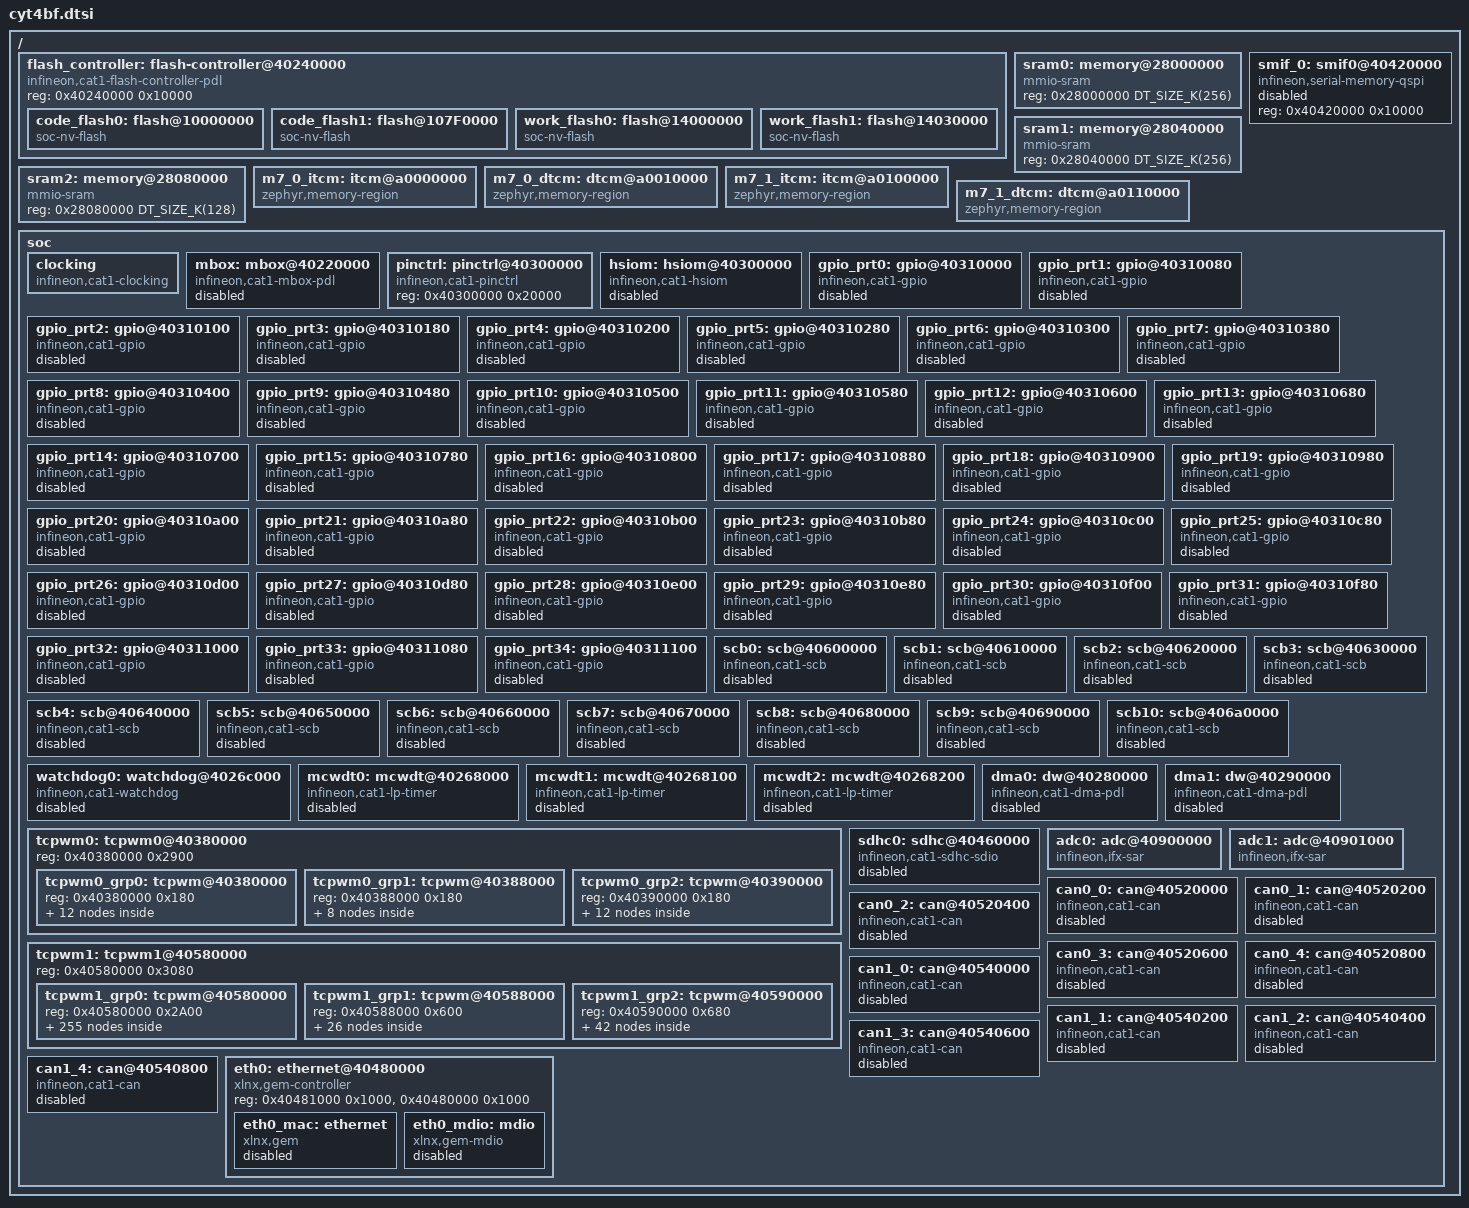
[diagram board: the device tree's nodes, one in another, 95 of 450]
/*
 * Copyright (c) 2023 Cypress Semiconductor Corporation (an Infineon company) or
 * an affiliate of Cypress Semiconductor Corporation
 *
 * SPDX-License-Identifier: Apache-2.0
 */

#include <mem.h>
#include <zephyr/dt-bindings/pinctrl/ifx_cat1-pinctrl.h>
#include <zephyr/dt-bindings/ethernet/xlnx_gem.h>
#include <zephyr/dt-bindings/memory-attr/memory-attr-arm.h>

/ {
	flash_controller: flash-controller@40240000 {
		compatible = "infineon,cat1-flash-controller-pdl";
		reg = <0x40240000 0x10000>;
		#address-cells = <1>;
		#size-cells = <1>;
		status = "okay";

		/* Code flash - Large sector (32KB Sectors) */
		code_flash0: flash@10000000 {
			compatible = "soc-nv-flash";
			reg = <0x10000000 DT_SIZE_K(8128)>;
			write-block-size = <512>;
			erase-block-size = <32768>;
		};

		/* Code flash - Large sector (8KB Sectors) */
		code_flash1: flash@107F0000 {
			compatible = "soc-nv-flash";
			reg = <0x107F0000 DT_SIZE_K(256)>;
			write-block-size = <512>;
			erase-block-size = <8192>;
		};

		/* Work flash - Large sector (2KB Sectors) */
		work_flash0: flash@14000000 {
			compatible = "soc-nv-flash";
			reg = <0x14000000 DT_SIZE_K(192)>;
			write-block-size = <64>;
			erase-block-size = <2048>;
		};

		/* Work flash - Small sector (128B Sectors) */
		work_flash1: flash@14030000 {
			compatible = "soc-nv-flash";
			reg = <0x14030000 DT_SIZE_K(64)>;
			write-block-size = <64>;
			erase-block-size = <128>;
		};
	};

	sram0: memory@28000000 {
		compatible = "mmio-sram";
		reg = <0x28000000 DT_SIZE_K(256)>;
	};
	sram1: memory@28040000 {
		compatible = "mmio-sram";
		reg = <0x28040000 DT_SIZE_K(256)>;
	};
	sram2: memory@28080000 {
		compatible = "mmio-sram";
		reg = <0x28080000 DT_SIZE_K(128)>;
	};

	smif_0: smif0@40420000 {
		compatible = "infineon,serial-memory-qspi";
		reg = <0x40420000 0x10000>;
		#address-cells = <1>;
		#size-cells = <1>;
		status = "disabled";
	};

	m7_0_itcm: itcm@a0000000 {
		compatible = "zephyr,memory-region", "arm,itcm";
		reg = <0xa0000000 DT_SIZE_K(64)>;
		zephyr,memory-region = "M7_0_ITCM";
	};
	m7_0_dtcm: dtcm@a0010000 {
		compatible = "zephyr,memory-region", "arm,dtcm";
		reg = <0xa0010000 DT_SIZE_K(64)>;
		zephyr,memory-region = "M7_0_DTCM";
	};
	m7_1_itcm: itcm@a0100000 {
		compatible = "zephyr,memory-region", "arm,itcm";
		reg = <0xA0100000 DT_SIZE_K(64)>;
		zephyr,memory-region = "M7_1_ITCM";
	};
	m7_1_dtcm: dtcm@a0110000 {
		compatible = "zephyr,memory-region", "arm,dtcm";
		reg = <0xA0110000 DT_SIZE_K(64)>;
		zephyr,memory-region = "M7_1_DTCM";
	};

	soc {
		clocking: clocking {
			compatible = "infineon,cat1-clocking";
		};

		mbox: mbox@40220000 {
			compatible = "infineon,cat1-mbox-pdl";
			reg = <0x40220000 0x10000>;
			system-interrupts = <0 3>;
			#mbox-cells = <1>;
			status = "disabled";
		};

		pinctrl: pinctrl@40300000 {
			compatible = "infineon,cat1-pinctrl";
			reg = <0x40300000 0x20000>;
		};
		hsiom: hsiom@40300000 {
			compatible = "infineon,cat1-hsiom";
			reg = <0x40300000 0x4000>;
			system-interrupts = <21 6>, <20 6>;
			status = "disabled";
		};

		gpio_prt0: gpio@40310000 {
			compatible = "infineon,cat1-gpio";
			reg = <0x40310000 0x80>;
			system-interrupts = <22 2>;
			gpio-controller;
			ngpios = <4>;
			status = "disabled";
			#gpio-cells = <2>;
		};
		gpio_prt1: gpio@40310080 {
			compatible = "infineon,cat1-gpio";
			reg = <0x40310080 0x80>;
			system-interrupts = <23 2>;
			gpio-controller;
			ngpios = <7>;
			status = "disabled";
			#gpio-cells = <2>;
		};
		gpio_prt2: gpio@40310100 {
			compatible = "infineon,cat1-gpio";
			reg = <0x40310100 0x80>;
			system-interrupts = <24 2>;
			gpio-controller;
			ngpios = <8>;
			status = "disabled";
			#gpio-cells = <2>;
		};
		gpio_prt3: gpio@40310180 {
			compatible = "infineon,cat1-gpio";
			reg = <0x40310180 0x80>;
			system-interrupts = <25 2>;
			gpio-controller;
			ngpios = <8>;
			status = "disabled";
			#gpio-cells = <2>;
		};
		gpio_prt4: gpio@40310200 {
			compatible = "infineon,cat1-gpio";
			reg = <0x40310200 0x80>;
			system-interrupts = <26 2>;
			gpio-controller;
			ngpios = <7>;
			status = "disabled";
			#gpio-cells = <2>;
		};
		gpio_prt5: gpio@40310280 {
			compatible = "infineon,cat1-gpio";
			reg = <0x40310280 0x80>;
			system-interrupts = <27 2>;
			gpio-controller;
			ngpios = <6>;
			status = "disabled";
			#gpio-cells = <2>;
		};
		gpio_prt6: gpio@40310300 {
			compatible = "infineon,cat1-gpio";
			reg = <0x40310300 0x80>;
			system-interrupts = <28 2>;
			gpio-controller;
			ngpios = <8>;
			status = "disabled";
			#gpio-cells = <2>;
		};
		gpio_prt7: gpio@40310380 {
			compatible = "infineon,cat1-gpio";
			reg = <0x40310380 0x80>;
			system-interrupts = <29 2>;
			gpio-controller;
			ngpios = <8>;
			status = "disabled";
			#gpio-cells = <2>;
		};
		gpio_prt8: gpio@40310400 {
			compatible = "infineon,cat1-gpio";
			reg = <0x40310400 0x80>;
			system-interrupts = <30 2>;
			gpio-controller;
			ngpios = <5>;
			status = "disabled";
			#gpio-cells = <2>;
		};
		gpio_prt9: gpio@40310480 {
			compatible = "infineon,cat1-gpio";
			reg = <0x40310480 0x80>;
			system-interrupts = <31 2>;
			gpio-controller;
			ngpios = <4>;
			status = "disabled";
			#gpio-cells = <2>;
		};
		gpio_prt10: gpio@40310500 {
			compatible = "infineon,cat1-gpio";
			reg = <0x40310500 0x80>;
			system-interrupts = <32 2>;
			gpio-controller;
			ngpios = <8>;
			status = "disabled";
			#gpio-cells = <2>;
		};
		gpio_prt11: gpio@40310580 {
			compatible = "infineon,cat1-gpio";
			reg = <0x40310580 0x80>;
			system-interrupts = <33 2>;
			gpio-controller;
			ngpios = <3>;
			status = "disabled";
			#gpio-cells = <2>;
		};
		gpio_prt12: gpio@40310600 {
			compatible = "infineon,cat1-gpio";
			reg = <0x40310600 0x80>;
			system-interrupts = <34 2>;
			gpio-controller;
			ngpios = <8>;
			status = "disabled";
			#gpio-cells = <2>;
		};
		gpio_prt13: gpio@40310680 {
			compatible = "infineon,cat1-gpio";
			reg = <0x40310680 0x80>;
			system-interrupts = <35 2>;
			gpio-controller;
			ngpios = <8>;
			status = "disabled";
			#gpio-cells = <2>;
		};
		gpio_prt14: gpio@40310700 {
			compatible = "infineon,cat1-gpio";
			reg = <0x40310700 0x80>;
			system-interrupts = <36 2>;
			gpio-controller;
			ngpios = <8>;
			status = "disabled";
			#gpio-cells = <2>;
		};
		gpio_prt15: gpio@40310780 {
			compatible = "infineon,cat1-gpio";
			reg = <0x40310780 0x80>;
			system-interrupts = <37 2>;
			gpio-controller;
			ngpios = <4>;
			status = "disabled";
			#gpio-cells = <2>;
		};
		gpio_prt16: gpio@40310800 {
			compatible = "infineon,cat1-gpio";
			reg = <0x40310800 0x80>;
			system-interrupts = <38 2>;
			gpio-controller;
			ngpios = <8>;
			status = "disabled";
			#gpio-cells = <2>;
		};
		gpio_prt17: gpio@40310880 {
			compatible = "infineon,cat1-gpio";
			reg = <0x40310880 0x80>;
			system-interrupts = <39 2>;
			gpio-controller;
			ngpios = <8>;
			status = "disabled";
			#gpio-cells = <2>;
		};
		gpio_prt18: gpio@40310900 {
			compatible = "infineon,cat1-gpio";
			reg = <0x40310900 0x80>;
			system-interrupts = <40 2>;
			gpio-controller;
			ngpios = <8>;
			status = "disabled";
			#gpio-cells = <2>;
		};
		gpio_prt19: gpio@40310980 {
			compatible = "infineon,cat1-gpio";
			reg = <0x40310980 0x80>;
			system-interrupts = <41 2>;
			gpio-controller;
			ngpios = <5>;
			status = "disabled";
			#gpio-cells = <2>;
		};
		gpio_prt20: gpio@40310a00 {
			compatible = "infineon,cat1-gpio";
			reg = <0x40310a00 0x80>;
			system-interrupts = <42 2>;
			gpio-controller;
			ngpios = <8>;
			status = "disabled";
			#gpio-cells = <2>;
		};
		gpio_prt21: gpio@40310a80 {
			compatible = "infineon,cat1-gpio";
			reg = <0x40310a80 0x80>;
			system-interrupts = <43 2>;
			gpio-controller;
			ngpios = <8>;
			status = "disabled";
			#gpio-cells = <2>;
		};
		gpio_prt22: gpio@40310b00 {
			compatible = "infineon,cat1-gpio";
			reg = <0x40310b00 0x80>;
			system-interrupts = <44 2>;
			gpio-controller;
			ngpios = <7>;
			status = "disabled";
			#gpio-cells = <2>;
		};
		gpio_prt23: gpio@40310b80 {
			compatible = "infineon,cat1-gpio";
			reg = <0x40310b80 0x80>;
			system-interrupts = <45 2>;
			gpio-controller;
			ngpios = <8>;
			status = "disabled";
			#gpio-cells = <2>;
		};
		gpio_prt24: gpio@40310c00 {
			compatible = "infineon,cat1-gpio";
			reg = <0x40310c00 0x80>;
			system-interrupts = <52 2>;
			gpio-controller;
			ngpios = <5>;
			status = "disabled";
			#gpio-cells = <2>;
		};
		gpio_prt25: gpio@40310c80 {
			compatible = "infineon,cat1-gpio";
			reg = <0x40310c80 0x80>;
			system-interrupts = <53 2>;
			gpio-controller;
			ngpios = <8>;
			status = "disabled";
			#gpio-cells = <2>;
		};
		gpio_prt26: gpio@40310d00 {
			compatible = "infineon,cat1-gpio";
			reg = <0x40310d00 0x80>;
			system-interrupts = <54 2>;
			gpio-controller;
			ngpios = <8>;
			status = "disabled";
			#gpio-cells = <2>;
		};
		gpio_prt27: gpio@40310d80 {
			compatible = "infineon,cat1-gpio";
			reg = <0x40310d80 0x80>;
			system-interrupts = <55 2>;
			gpio-controller;
			ngpios = <8>;
			status = "disabled";
			#gpio-cells = <2>;
		};
		gpio_prt28: gpio@40310e00 {
			compatible = "infineon,cat1-gpio";
			reg = <0x40310e00 0x80>;
			system-interrupts = <46 2>;
			gpio-controller;
			ngpios = <8>;
			status = "disabled";
			#gpio-cells = <2>;
		};
		gpio_prt29: gpio@40310e80 {
			compatible = "infineon,cat1-gpio";
			reg = <0x40310e80 0x80>;
			system-interrupts = <47 2>;
			gpio-controller;
			ngpios = <8>;
			status = "disabled";
			#gpio-cells = <2>;
		};
		gpio_prt30: gpio@40310f00 {
			compatible = "infineon,cat1-gpio";
			reg = <0x40310f00 0x80>;
			system-interrupts = <48 2>;
			gpio-controller;
			ngpios = <4>;
			status = "disabled";
			#gpio-cells = <2>;
		};
		gpio_prt31: gpio@40310f80 {
			compatible = "infineon,cat1-gpio";
			reg = <0x40310f80 0x80>;
			system-interrupts = <49 2>;
			gpio-controller;
			ngpios = <3>;
			status = "disabled";
			#gpio-cells = <2>;
		};
		gpio_prt32: gpio@40311000 {
			compatible = "infineon,cat1-gpio";
			reg = <0x40311000 0x80>;
			system-interrupts = <50 2>;
			gpio-controller;
			ngpios = <8>;
			status = "disabled";
			#gpio-cells = <2>;
		};
		gpio_prt33: gpio@40311080 {
			compatible = "infineon,cat1-gpio";
			reg = <0x40311080 0x80>;
			system-interrupts = <56 2>;
			gpio-controller;
			ngpios = <8>;
			status = "disabled";
			#gpio-cells = <2>;
		};
		gpio_prt34: gpio@40311100 {
			compatible = "infineon,cat1-gpio";
			reg = <0x40311100 0x80>;
			system-interrupts = <57 2>;
			gpio-controller;
			ngpios = <8>;
			status = "disabled";
			#gpio-cells = <2>;
		};

		scb0: scb@40600000 {
			compatible = "infineon,cat1-scb";
			reg = <0x40600000 0xfd0>;
			system-interrupts = <18 6>;
			status = "disabled";
		};
		scb1: scb@40610000 {
			compatible = "infineon,cat1-scb";
			reg = <0x40610000 0xfd0>;
			system-interrupts = <113 6>;
			status = "disabled";
		};
		scb2: scb@40620000 {
			compatible = "infineon,cat1-scb";
			reg = <0x40620000 0xfd0>;
			system-interrupts = <114 6>;
			status = "disabled";
		};
		scb3: scb@40630000 {
			compatible = "infineon,cat1-scb";
			reg = <0x40630000 0xfd0>;
			system-interrupts = <115 6>;
			status = "disabled";
		};
		scb4: scb@40640000 {
			compatible = "infineon,cat1-scb";
			reg = <0x40640000 0xfd0>;
			system-interrupts = <116 6>;
			status = "disabled";
		};
		scb5: scb@40650000 {
			compatible = "infineon,cat1-scb";
			reg = <0x40650000 0xfd0>;
			system-interrupts = <117 6>;
			status = "disabled";
		};
		scb6: scb@40660000 {
			compatible = "infineon,cat1-scb";
			reg = <0x40660000 0xfd0>;
			system-interrupts = <118 6>;
			status = "disabled";
		};
		scb7: scb@40670000 {
			compatible = "infineon,cat1-scb";
			reg = <0x40670000 0xfd0>;
			system-interrupts = <119 6>;
			status = "disabled";
		};
		scb8: scb@40680000 {
			compatible = "infineon,cat1-scb";
			reg = <0x40680000 0xfd0>;
			system-interrupts = <120 6>;
			status = "disabled";
		};
		scb9: scb@40690000 {
			compatible = "infineon,cat1-scb";
			reg = <0x40690000 0xfd0>;
			system-interrupts = <121 6>;
			status = "disabled";
		};
		scb10: scb@406a0000 {
			compatible = "infineon,cat1-scb";
			reg = <0x406a0000 0xfd0>;
			system-interrupts = <122 6>;
			status = "disabled";
		};

		watchdog0: watchdog@4026c000 {
			compatible = "infineon,cat1-watchdog";
			reg = <0x4026c000 0x80>;
			system-interrupts = <16 6>;
			status = "disabled";
		};

		mcwdt0: mcwdt@40268000 {
			compatible = "infineon,cat1-lp-timer";
			reg = <0x40268000 0x100>;
			system-interrupts = <13 6>;
			status = "disabled";
		};
		mcwdt1: mcwdt@40268100 {
			compatible = "infineon,cat1-lp-timer";
			reg = <0x40268100 0x100>;
			system-interrupts = <14 6>;
			status = "disabled";
		};
		mcwdt2: mcwdt@40268200 {
			compatible = "infineon,cat1-lp-timer";
			reg = <0x40268200 0x100>;
			system-interrupts = <15 6>;
			status = "disabled";
		};

			tcpwm0: tcpwm0@40380000 {
			reg = <0x40380000 0x2900>;
			#address-cells = <1>;
			#size-cells = <1>;
			tcpwm0_grp0: tcpwm@40380000 {
				reg = <0x40380000 0x180>;
				#address-cells = <1>;
				#size-cells = <1>;
				tcpwm0_grp0_pwm: pwm@40380000 {
					compatible = "infineon,cat1-pwm";
					reg = <0x40380000 0x180>;
					#address-cells = <1>;
					#size-cells = <0>;
					#pwm-cells = <3>;
					resolution = <16>;
					status = "disabled";

					pwm_ch0_0: channel@0 {
						reg = <0x0>;
						system-interrupts = <519 4>;
						status = "disabled";
					};

					pwm_ch0_1: channel@1 {
						reg = <0x1>;
						system-interrupts = <520 4>;
						status = "disabled";
					};

					pwm_ch0_2: channel@2 {
						reg = <0x2>;
						system-interrupts = <521 4>;
						status = "disabled";
					};
				};

				tcpwm0_grp0_tgpio: tgpio@40380000 {
					compatible = "infineon,tcpwm-tgpio";
					reg = <0x40380000 0x180>;
					#address-cells = <1>;
					#size-cells = <0>;
					status = "disabled";

					tgpio_ch0_0: channel@0 {
						reg = <0x0>;
						system-interrupts = <519 4>;
						status = "disabled";
					};

					tgpio_ch0_1: channel@1 {
						reg = <0x1>;
						system-interrupts = <520 4>;
						status = "disabled";
					};

					tgpio_ch0_2: channel@2 {
						reg = <0x2>;
						system-interrupts = <521 4>;
						status = "disabled";
					};
				};
				tcpwm0_grp0_cnt: tcpwm@40380000 {
					compatible = "infineon,tcpwm";
					reg = <0x40380000 0x180>;
					#address-cells = <1>;
					#size-cells = <1>;
					resolution = <16>;
					status = "disabled";

					counter0_0: counter@40380000 {
						compatible = "infineon,tcpwm-counter";
						reg = <0x40380000 0x80>;
						system-interrupts = <519 4>;
						status = "disabled";
					};

					counter0_1: counter@40380080 {
						compatible = "infineon,tcpwm-counter";
						reg = <0x40380080 0x80>;
						system-interrupts = <520 4>;
						status = "disabled";
					};

					counter0_2: counter@40380100 {
						compatible = "infineon,tcpwm-counter";
						reg = <0x40380100 0x80>;
						system-interrupts = <521 4>;
						status = "disabled";
					};
				};
			};
			tcpwm0_grp1: tcpwm@40388000 {
				reg = <0x40388000 0x180>;
				#address-cells = <1>;
				#size-cells = <1>;
				tcpwm0_grp1_pwm: pwm@40388000 {
					compatible = "infineon,cat1-pwm";
					reg = <0x40388000 0x180>;
					#address-cells = <1>;
					#size-cells = <0>;
					#pwm-cells = <3>;
					resolution = <16>;
					status = "disabled";

					pwm_ch1_0: channel@0 {
						reg = <0x0>;
						system-interrupts = <534 4>;
						status = "disabled";
					};

					pwm_ch1_1: channel@1 {
						reg = <0x1>;
						system-interrupts = <535 4>;
						status = "disabled";
					};

					pwm_ch1_2: channel@2 {
						reg = <0x2>;
						system-interrupts = <536 4>;
						status = "disabled";
					};
				};

			tcpwm0_grp1_cnt: tcpwm@40388000 {
					compatible = "infineon,tcpwm";
					reg = <0x40388000 0x180>;
					#address-cells = <1>;
					#size-cells = <1>;
					resolution = <16>;
					status = "disabled";

					counter1_0: counter@40388000 {
						compatible = "infineon,tcpwm-counter";
						reg = <0x40388000 0x80>;
						system-interrupts = <534 4>;
						status = "disabled";
					};

					counter1_1: counter@40388080 {
						compatible = "infineon,tcpwm-counter";
						reg = <0x40388080 0x80>;
						system-interrupts = <535 4>;
						status = "disabled";
					};

					counter1_2: counter@40388100 {
						compatible = "infineon,tcpwm-counter";
						reg = <0x40388100 0x80>;
						system-interrupts = <536 4>;
						status = "disabled";
					};
				};
			};

			tcpwm0_grp2: tcpwm@40390000 {
				reg = <0x40390000 0x180>;
				#address-cells = <1>;
				#size-cells = <1>;
				tcpwm0_grp2_pwm: pwm@40390000 {
					compatible = "infineon,cat1-pwm";
					reg = <0x40390000 0x180>;
					#address-cells = <1>;
					#size-cells = <0>;
					#pwm-cells = <3>;
					resolution = <32>;
					status = "disabled";

					pwm_ch2_0: channel@0 {
						reg = <0x0>;
						system-interrupts = <550 4>;
						status = "disabled";
					};

					pwm_ch2_1: channel@1 {
						reg = <0x1>;
						system-interrupts = <551 4>;
						status = "disabled";
					};

					pwm_ch2_2: channel@2 {
						reg = <0x2>;
						system-interrupts = <552 4>;
						status = "disabled";
					};
				};

				tcpwm0_grp2_tgpio: tgpio@40390000 {
					compatible = "infineon,tcpwm-tgpio";
					reg = <0x40390000 0x180>;
					#address-cells = <1>;
					#size-cells = <0>;
					status = "disabled";

					tgpio_ch2_0: channel@0 {
						reg = <0x0>;
						system-interrupts = <550 4>;
						status = "disabled";
					};

					tgpio_ch2_1: channel@1 {
						reg = <0x1>;
						system-interrupts = <551 4>;
						status = "disabled";
					};

					tgpio_ch2_2: channel@2 {
						reg = <0x2>;
						system-interrupts = <552 4>;
						status = "disabled";
					};
				};
			tcpwm0_grp2_cnt: tcpwm@40390000 {
					compatible = "infineon,tcpwm";
					reg = <0x40390000 0x180>;
					#address-cells = <1>;
					#size-cells = <1>;
					resolution = <32>;
					status = "disabled";

					counter2_0: counter@40390000 {
						compatible = "infineon,tcpwm-counter";
						reg = <0x40390000 0x80>;
						system-interrupts = <550 4>;
						status = "disabled";
					};

					counter2_1: counter@40390080 {
						compatible = "infineon,tcpwm-counter";
						reg = <0x40390080 0x80>;
						system-interrupts = <551 4>;
						status = "disabled";
					};

					counter2_2: counter@40390100 {
						compatible = "infineon,tcpwm-counter";
						reg = <0x40390100 0x80>;
						system-interrupts = <552 4>;
						status = "disabled";
					};
				};
			};
		};


		tcpwm1: tcpwm1@40580000 {
			reg = <0x40580000 0x3080>;
			#address-cells = <1>;
			#size-cells = <1>;
			tcpwm1_grp0: tcpwm@40580000 {
				reg = <0x40580000 0x2A00>;
				#address-cells = <1>;
				#size-cells = <1>;
				tcpwm1_grp0_pwm: pwm@40580000 {
					compatible = "infineon,cat1-pwm";
					reg = <0x40580000 0x2A00>;
					#address-cells = <1>;
					#size-cells = <0>;
					#pwm-cells = <3>;
					resolution = <16>;
					status = "disabled";

					pwm1_ch0_0: channel@0 {
						reg = <0x0>;
						system-interrupts = <435 4>;
						status = "disabled";
					};

					pwm1_ch0_1: channel@1 {
						reg = <0x1>;
						system-interrupts = <436 4>;
						status = "disabled";
					};

					pwm1_ch0_2: channel@2 {
						reg = <0x2>;
						system-interrupts = <437 4>;
						status = "disabled";
					};

					pwm1_ch0_3: channel@3 {
						reg = <0x3>;
						system-interrupts = <438 4>;
						status = "disabled";
					};

					pwm1_ch0_4: channel@4 {
						reg = <0x4>;
						system-interrupts = <439 4>;
						status = "disabled";
					};

					pwm1_ch0_5: channel@5 {
						reg = <0x5>;
						system-interrupts = <440 4>;
						status = "disabled";
					};

					pwm1_ch0_6: channel@6 {
						reg = <0x6>;
						system-interrupts = <441 4>;
						status = "disabled";
					};

					pwm1_ch0_7: channel@7 {
						reg = <0x7>;
						system-interrupts = <442 4>;
						status = "disabled";
					};

					pwm1_ch0_8: channel@8 {
						reg = <0x8>;
						system-interrupts = <443 4>;
						status = "disabled";
					};

					pwm1_ch0_9: channel@9 {
						reg = <0x9>;
						system-interrupts = <444 4>;
						status = "disabled";
					};

					pwm1_ch0_10: channel@10 {
						reg = <0xA>;
						system-interrupts = <445 4>;
						status = "disabled";
					};

					pwm1_ch0_11: channel@11 {
						reg = <0xB>;
						system-interrupts = <446 4>;
						status = "disabled";
					};

					pwm1_ch0_12: channel@12 {
						reg = <0xC>;
						system-interrupts = <447 4>;
						status = "disabled";
					};

					pwm1_ch0_13: channel@13 {
						reg = <0xD>;
						system-interrupts = <448 4>;
						status = "disabled";
					};

					pwm1_ch0_14: channel@14 {
						reg = <0xE>;
						system-interrupts = <449 4>;
						status = "disabled";
					};

					pwm1_ch0_15: channel@15 {
						reg = <0xF>;
						system-interrupts = <450 4>;
						status = "disabled";
					};

					pwm1_ch0_16: channel@16 {
						reg = <0x10>;
						system-interrupts = <451 4>;
						status = "disabled";
					};

					pwm1_ch0_17: channel@17 {
						reg = <0x11>;
						system-interrupts = <452 4>;
						status = "disabled";
					};

					pwm1_ch0_18: channel@18 {
						reg = <0x12>;
						system-interrupts = <453 4>;
						status = "disabled";
					};

					pwm1_ch0_19: channel@19 {
						reg = <0x13>;
						system-interrupts = <454 4>;
						status = "disabled";
					};

					pwm1_ch0_20: channel@20 {
						reg = <0x14>;
						system-interrupts = <455 4>;
						status = "disabled";
					};

					pwm1_ch0_21: channel@21 {
						reg = <0x15>;
						system-interrupts = <456 4>;
						status = "disabled";
					};

					pwm1_ch0_22: channel@22 {
						reg = <0x16>;
						system-interrupts = <457 4>;
						status = "disabled";
					};

					pwm1_ch0_23: channel@23 {
						reg = <0x17>;
						system-interrupts = <458 4>;
						status = "disabled";
					};

					pwm1_ch0_24: channel@24 {
						reg = <0x18>;
						system-interrupts = <459 4>;
						status = "disabled";
					};

					pwm1_ch0_25: channel@25 {
						reg = <0x19>;
						system-interrupts = <460 4>;
						status = "disabled";
					};

					pwm1_ch0_26: channel@26 {
						reg = <0x1A>;
						system-interrupts = <461 4>;
						status = "disabled";
					};

					pwm1_ch0_27: channel@27 {
						reg = <0x1B>;
						system-interrupts = <462 4>;
						status = "disabled";
					};

					pwm1_ch0_28: channel@28 {
						reg = <0x1C>;
						system-interrupts = <463 4>;
						status = "disabled";
					};

					pwm1_ch0_29: channel@29 {
						reg = <0x1D>;
						system-interrupts = <464 4>;
						status = "disabled";
					};

					pwm1_ch0_30: channel@30 {
						reg = <0x1E>;
						system-interrupts = <465 4>;
						status = "disabled";
					};

					pwm1_ch0_31: channel@31 {
						reg = <0x1F>;
						system-interrupts = <466 4>;
						status = "disabled";
					};

					pwm1_ch0_32: channel@32 {
						reg = <0x20>;
						system-interrupts = <467 4>;
						status = "disabled";
					};

					pwm1_ch0_33: channel@33 {
						reg = <0x21>;
						system-interrupts = <468 4>;
						status = "disabled";
					};

					pwm1_ch0_34: channel@34 {
						reg = <0x22>;
						system-interrupts = <469 4>;
						status = "disabled";
					};

					pwm1_ch0_35: channel@35 {
						reg = <0x23>;
						system-interrupts = <470 4>;
						status = "disabled";
					};

					pwm1_ch0_36: channel@36 {
						reg = <0x24>;
						system-interrupts = <471 4>;
						status = "disabled";
					};

					pwm1_ch0_37: channel@37 {
						reg = <0x25>;
						system-interrupts = <472 4>;
						status = "disabled";
					};

					pwm1_ch0_38: channel@38 {
						reg = <0x26>;
						system-interrupts = <473 4>;
						status = "disabled";
					};

					pwm1_ch0_39: channel@39 {
						reg = <0x27>;
						system-interrupts = <474 4>;
						status = "disabled";
					};

					pwm1_ch0_40: channel@40 {
						reg = <0x28>;
						system-interrupts = <475 4>;
						status = "disabled";
					};

					pwm1_ch0_41: channel@41 {
						reg = <0x29>;
						system-interrupts = <476 4>;
						status = "disabled";
					};

					pwm1_ch0_42: channel@42 {
						reg = <0x2A>;
						system-interrupts = <477 4>;
						status = "disabled";
					};

					pwm1_ch0_43: channel@43 {
						reg = <0x2B>;
						system-interrupts = <478 4>;
						status = "disabled";
					};

					pwm1_ch0_44: channel@44 {
						reg = <0x2C>;
						system-interrupts = <479 4>;
						status = "disabled";
					};

					pwm1_ch0_45: channel@45 {
						reg = <0x2D>;
						system-interrupts = <480 4>;
						status = "disabled";
					};

					pwm1_ch0_46: channel@46 {
						reg = <0x2E>;
						system-interrupts = <481 4>;
						status = "disabled";
					};

					pwm1_ch0_47: channel@47 {
						reg = <0x2F>;
						system-interrupts = <482 4>;
						status = "disabled";
					};

					pwm1_ch0_48: channel@48 {
						reg = <0x30>;
						system-interrupts = <483 4>;
						status = "disabled";
					};

					pwm1_ch0_49: channel@49 {
						reg = <0x31>;
						system-interrupts = <484 4>;
						status = "disabled";
					};

					pwm1_ch0_50: channel@50 {
						reg = <0x32>;
						system-interrupts = <485 4>;
						status = "disabled";
					};

					pwm1_ch0_51: channel@51 {
						reg = <0x33>;
						system-interrupts = <486 4>;
						status = "disabled";
					};

					pwm1_ch0_52: channel@52 {
						reg = <0x34>;
						system-interrupts = <487 4>;
						status = "disabled";
					};

					pwm1_ch0_53: channel@53 {
						reg = <0x35>;
						system-interrupts = <488 4>;
						status = "disabled";
					};

					pwm1_ch0_54: channel@54 {
						reg = <0x36>;
						system-interrupts = <489 4>;
						status = "disabled";
					};

					pwm1_ch0_55: channel@55 {
						reg = <0x37>;
						system-interrupts = <490 4>;
						status = "disabled";
					};

					pwm1_ch0_56: channel@56 {
						reg = <0x38>;
						system-interrupts = <491 4>;
						status = "disabled";
					};

					pwm1_ch0_57: channel@57 {
						reg = <0x39>;
						system-interrupts = <492 4>;
						status = "disabled";
					};

					pwm1_ch0_58: channel@58 {
						reg = <0x3A>;
						system-interrupts = <493 4>;
						status = "disabled";
					};

					pwm1_ch0_59: channel@59 {
						reg = <0x3B>;
						system-interrupts = <494 4>;
						status = "disabled";
					};

					pwm1_ch0_60: channel@60 {
						reg = <0x3C>;
						system-interrupts = <495 4>;
						status = "disabled";
					};

					pwm1_ch0_61: channel@61 {
						reg = <0x3D>;
						system-interrupts = <496 4>;
						status = "disabled";
					};

					pwm1_ch0_62: channel@62 {
						reg = <0x3E>;
						system-interrupts = <497 4>;
						status = "disabled";
					};

					pwm1_ch0_63: channel@63 {
						reg = <0x3F>;
						system-interrupts = <498 4>;
						status = "disabled";
					};

					pwm1_ch0_64: channel@64 {
						reg = <0x40>;
						system-interrupts = <499 4>;
						status = "disabled";
					};

					pwm1_ch0_65: channel@65 {
						reg = <0x41>;
						system-interrupts = <500 4>;
						status = "disabled";
					};

					pwm1_ch0_66: channel@66 {
						reg = <0x42>;
						system-interrupts = <501 4>;
						status = "disabled";
					};

					pwm1_ch0_67: channel@67 {
						reg = <0x43>;
						system-interrupts = <502 4>;
						status = "disabled";
					};

					pwm1_ch0_68: channel@68 {
						reg = <0x44>;
						system-interrupts = <503 4>;
						status = "disabled";
					};

					pwm1_ch0_69: channel@69 {
						reg = <0x45>;
						system-interrupts = <504 4>;
						status = "disabled";
					};

					pwm1_ch0_70: channel@70 {
						reg = <0x46>;
						system-interrupts = <505 4>;
						status = "disabled";
					};

					pwm1_ch0_71: channel@71 {
						reg = <0x47>;
						system-interrupts = <506 4>;
						status = "disabled";
					};

					pwm1_ch0_72: channel@72 {
						reg = <0x48>;
						system-interrupts = <507 4>;
						status = "disabled";
					};

					pwm1_ch0_73: channel@73 {
						reg = <0x49>;
						system-interrupts = <508 4>;
						status = "disabled";
					};

					pwm1_ch0_74: channel@74 {
						reg = <0x4A>;
						system-interrupts = <509 4>;
						status = "disabled";
					};

					pwm1_ch0_75: channel@75 {
						reg = <0x4B>;
						system-interrupts = <510 4>;
						status = "disabled";
					};

					pwm1_ch0_76: channel@76 {
						reg = <0x4C>;
						system-interrupts = <511 4>;
						status = "disabled";
					};

					pwm1_ch0_77: channel@77 {
						reg = <0x4D>;
						system-interrupts = <512 4>;
						status = "disabled";
					};

					pwm1_ch0_78: channel@78 {
						reg = <0x4E>;
						system-interrupts = <513 4>;
						status = "disabled";
					};

					pwm1_ch0_79: channel@79 {
						reg = <0x4F>;
						system-interrupts = <514 4>;
						status = "disabled";
					};

					pwm1_ch0_80: channel@80 {
						reg = <0x50>;
						system-interrupts = <515 4>;
						status = "disabled";
					};

					pwm1_ch0_81: channel@81 {
						reg = <0x51>;
						system-interrupts = <516 4>;
						status = "disabled";
					};

					pwm1_ch0_82: channel@82 {
						reg = <0x52>;
						system-interrupts = <517 4>;
						status = "disabled";
					};

					pwm1_ch0_83: channel@83 {
						reg = <0x53>;
						system-interrupts = <518 4>;
						status = "disabled";
					};
				};

				tcpwm1_grp0_tgpio: tgpio@40580000 {
					compatible = "infineon,tcpwm-tgpio";
					reg = <0x40580000 0x2A00>;
					#address-cells = <1>;
					#size-cells = <0>;
					status = "disabled";

					tgpio1_ch0_0: channel@0 {
						reg = <0x0>;
						system-interrupts = <435 4>;
						status = "disabled";
					};

					tgpio1_ch0_1: channel@1 {
						reg = <0x1>;
						system-interrupts = <436 4>;
						status = "disabled";
					};

					tgpio1_ch0_2: channel@2 {
						reg = <0x2>;
						system-interrupts = <437 4>;
						status = "disabled";
					};

					tgpio1_ch0_3: channel@3 {
						reg = <0x3>;
						system-interrupts = <438 4>;
						status = "disabled";
					};

					tgpio1_ch0_4: channel@4 {
						reg = <0x4>;
						system-interrupts = <439 4>;
						status = "disabled";
					};

					tgpio1_ch0_5: channel@5 {
						reg = <0x5>;
						system-interrupts = <440 4>;
						status = "disabled";
					};

					tgpio1_ch0_6: channel@6 {
						reg = <0x6>;
						system-interrupts = <441 4>;
						status = "disabled";
					};

					tgpio1_ch0_7: channel@7 {
						reg = <0x7>;
						system-interrupts = <442 4>;
						status = "disabled";
					};

					tgpio1_ch0_8: channel@8 {
						reg = <0x8>;
						system-interrupts = <443 4>;
						status = "disabled";
					};

					tgpio1_ch0_9: channel@9 {
						reg = <0x9>;
						system-interrupts = <444 4>;
						status = "disabled";
					};

					tgpio1_ch0_10: channel@10 {
						reg = <0xA>;
						system-interrupts = <445 4>;
						status = "disabled";
					};

					tgpio1_ch0_11: channel@11 {
						reg = <0xB>;
						system-interrupts = <446 4>;
						status = "disabled";
					};

					tgpio1_ch0_12: channel@12 {
						reg = <0xC>;
						system-interrupts = <447 4>;
						status = "disabled";
					};

					tgpio1_ch0_13: channel@13 {
						reg = <0xD>;
						system-interrupts = <448 4>;
						status = "disabled";
					};

					tgpio1_ch0_14: channel@14 {
						reg = <0xE>;
						system-interrupts = <449 4>;
						status = "disabled";
					};

					tgpio1_ch0_15: channel@15 {
						reg = <0xF>;
						system-interrupts = <450 4>;
						status = "disabled";
					};

					tgpio1_ch0_16: channel@16 {
						reg = <0x10>;
						system-interrupts = <451 4>;
						status = "disabled";
					};

					tgpio1_ch0_17: channel@17 {
						reg = <0x11>;
						system-interrupts = <452 4>;
						status = "disabled";
					};

					tgpio1_ch0_18: channel@18 {
						reg = <0x12>;
						system-interrupts = <453 4>;
						status = "disabled";
					};

					tgpio1_ch0_19: channel@19 {
						reg = <0x13>;
						system-interrupts = <454 4>;
						status = "disabled";
					};

					tgpio1_ch0_20: channel@20 {
						reg = <0x14>;
						system-interrupts = <455 4>;
						status = "disabled";
					};

					tgpio1_ch0_21: channel@21 {
						reg = <0x15>;
						system-interrupts = <456 4>;
						status = "disabled";
					};

					tgpio1_ch0_22: channel@22 {
						reg = <0x16>;
						system-interrupts = <457 4>;
						status = "disabled";
					};

					tgpio1_ch0_23: channel@23 {
						reg = <0x17>;
						system-interrupts = <458 4>;
						status = "disabled";
					};

					tgpio1_ch0_24: channel@24 {
						reg = <0x18>;
						system-interrupts = <459 4>;
						status = "disabled";
					};

					tgpio1_ch0_25: channel@25 {
						reg = <0x19>;
						system-interrupts = <460 4>;
						status = "disabled";
					};

					tgpio1_ch0_26: channel@26 {
						reg = <0x1A>;
						system-interrupts = <461 4>;
						status = "disabled";
					};

					tgpio1_ch0_27: channel@27 {
						reg = <0x1B>;
						system-interrupts = <462 4>;
						status = "disabled";
					};

					tgpio1_ch0_28: channel@28 {
						reg = <0x1C>;
						system-interrupts = <463 4>;
						status = "disabled";
					};

					tgpio1_ch0_29: channel@29 {
						reg = <0x1D>;
						system-interrupts = <464 4>;
						status = "disabled";
					};

					tgpio1_ch0_30: channel@30 {
						reg = <0x1E>;
						system-interrupts = <465 4>;
						status = "disabled";
					};

					tgpio1_ch0_31: channel@31 {
						reg = <0x1F>;
						system-interrupts = <466 4>;
						status = "disabled";
					};

					tgpio1_ch0_32: channel@32 {
						reg = <0x20>;
						system-interrupts = <467 4>;
						status = "disabled";
					};

					tgpio1_ch0_33: channel@33 {
						reg = <0x21>;
						system-interrupts = <468 4>;
						status = "disabled";
					};

					tgpio1_ch0_34: channel@34 {
						reg = <0x22>;
						system-interrupts = <469 4>;
						status = "disabled";
					};

					tgpio1_ch0_35: channel@35 {
						reg = <0x23>;
						system-interrupts = <470 4>;
						status = "disabled";
					};

					tgpio1_ch0_36: channel@36 {
						reg = <0x24>;
						system-interrupts = <471 4>;
						status = "disabled";
					};

					tgpio1_ch0_37: channel@37 {
						reg = <0x25>;
						system-interrupts = <472 4>;
						status = "disabled";
					};

					tgpio1_ch0_38: channel@38 {
						reg = <0x26>;
						system-interrupts = <473 4>;
						status = "disabled";
					};

					tgpio1_ch0_39: channel@39 {
						reg = <0x27>;
						system-interrupts = <474 4>;
						status = "disabled";
					};

					tgpio1_ch0_40: channel@40 {
						reg = <0x28>;
						system-interrupts = <475 4>;
						status = "disabled";
					};

					tgpio1_ch0_41: channel@41 {
						reg = <0x29>;
						system-interrupts = <476 4>;
						status = "disabled";
					};

					tgpio1_ch0_42: channel@42 {
						reg = <0x2A>;
						system-interrupts = <477 4>;
						status = "disabled";
					};

					tgpio1_ch0_43: channel@43 {
						reg = <0x2B>;
						system-interrupts = <478 4>;
						status = "disabled";
					};

					tgpio1_ch0_44: channel@44 {
						reg = <0x2C>;
						system-interrupts = <479 4>;
						status = "disabled";
					};

					tgpio1_ch0_45: channel@45 {
						reg = <0x2D>;
						system-interrupts = <480 4>;
						status = "disabled";
					};

					tgpio1_ch0_46: channel@46 {
						reg = <0x2E>;
						system-interrupts = <481 4>;
						status = "disabled";
					};

					tgpio1_ch0_47: channel@47 {
						reg = <0x2F>;
						system-interrupts = <482 4>;
						status = "disabled";
					};

					tgpio1_ch0_48: channel@48 {
						reg = <0x30>;
						system-interrupts = <483 4>;
						status = "disabled";
					};

					tgpio1_ch0_49: channel@49 {
						reg = <0x31>;
						system-interrupts = <484 4>;
						status = "disabled";
					};

					tgpio1_ch0_50: channel@50 {
						reg = <0x32>;
						system-interrupts = <485 4>;
						status = "disabled";
					};

					tgpio1_ch0_51: channel@51 {
						reg = <0x33>;
						system-interrupts = <486 4>;
						status = "disabled";
					};

					tgpio1_ch0_52: channel@52 {
						reg = <0x34>;
						system-interrupts = <487 4>;
						status = "disabled";
					};

					tgpio1_ch0_53: channel@53 {
						reg = <0x35>;
						system-interrupts = <488 4>;
						status = "disabled";
					};

					tgpio1_ch0_54: channel@54 {
						reg = <0x36>;
						system-interrupts = <489 4>;
						status = "disabled";
					};

					tgpio1_ch0_55: channel@55 {
						reg = <0x37>;
						system-interrupts = <490 4>;
						status = "disabled";
					};

					tgpio1_ch0_56: channel@56 {
						reg = <0x38>;
						system-interrupts = <491 4>;
						status = "disabled";
					};

					tgpio1_ch0_57: channel@57 {
						reg = <0x39>;
						system-interrupts = <492 4>;
						status = "disabled";
					};

					tgpio1_ch0_58: channel@58 {
						reg = <0x3A>;
						system-interrupts = <493 4>;
						status = "disabled";
					};

					tgpio1_ch0_59: channel@59 {
						reg = <0x3B>;
						system-interrupts = <494 4>;
						status = "disabled";
					};

					tgpio1_ch0_60: channel@60 {
						reg = <0x3C>;
						system-interrupts = <495 4>;
						status = "disabled";
					};

					tgpio1_ch0_61: channel@61 {
						reg = <0x3D>;
						system-interrupts = <496 4>;
						status = "disabled";
					};

					tgpio1_ch0_62: channel@62 {
						reg = <0x3E>;
						system-interrupts = <497 4>;
						status = "disabled";
					};

					tgpio1_ch0_63: channel@63 {
						reg = <0x3F>;
						system-interrupts = <498 4>;
						status = "disabled";
					};

					tgpio1_ch0_64: channel@64 {
						reg = <0x40>;
						system-interrupts = <499 4>;
						status = "disabled";
					};

					tgpio1_ch0_65: channel@65 {
						reg = <0x41>;
						system-interrupts = <500 4>;
						status = "disabled";
					};

					tgpio1_ch0_66: channel@66 {
						reg = <0x42>;
						system-interrupts = <501 4>;
						status = "disabled";
					};

					tgpio1_ch0_67: channel@67 {
						reg = <0x43>;
						system-interrupts = <502 4>;
						status = "disabled";
					};

					tgpio1_ch0_68: channel@68 {
						reg = <0x44>;
						system-interrupts = <503 4>;
						status = "disabled";
					};

					tgpio1_ch0_69: channel@69 {
						reg = <0x45>;
						system-interrupts = <504 4>;
						status = "disabled";
					};

					tgpio1_ch0_70: channel@70 {
						reg = <0x46>;
						system-interrupts = <505 4>;
						status = "disabled";
					};

					tgpio1_ch0_71: channel@71 {
						reg = <0x47>;
						system-interrupts = <506 4>;
						status = "disabled";
					};

					tgpio1_ch0_72: channel@72 {
						reg = <0x48>;
						system-interrupts = <507 4>;
						status = "disabled";
					};

					tgpio1_ch0_73: channel@73 {
						reg = <0x49>;
						system-interrupts = <508 4>;
						status = "disabled";
					};

					tgpio1_ch0_74: channel@74 {
						reg = <0x4A>;
						system-interrupts = <509 4>;
						status = "disabled";
					};

					tgpio1_ch0_75: channel@75 {
						reg = <0x4B>;
						system-interrupts = <510 4>;
						status = "disabled";
					};

					tgpio1_ch0_76: channel@76 {
						reg = <0x4C>;
						system-interrupts = <511 4>;
						status = "disabled";
					};

					tgpio1_ch0_77: channel@77 {
						reg = <0x4D>;
						system-interrupts = <512 4>;
						status = "disabled";
					};

					tgpio1_ch0_78: channel@78 {
						reg = <0x4E>;
						system-interrupts = <513 4>;
						status = "disabled";
					};

					tgpio1_ch0_79: channel@79 {
						reg = <0x4F>;
						system-interrupts = <514 4>;
						status = "disabled";
					};

					tgpio1_ch0_80: channel@80 {
						reg = <0x50>;
						system-interrupts = <515 4>;
						status = "disabled";
					};

					tgpio1_ch0_81: channel@81 {
						reg = <0x51>;
						system-interrupts = <516 4>;
						status = "disabled";
					};

					tgpio1_ch0_82: channel@82 {
						reg = <0x52>;
						system-interrupts = <517 4>;
						status = "disabled";
					};

					tgpio1_ch0_83: channel@83 {
						reg = <0x53>;
						system-interrupts = <518 4>;
						status = "disabled";
					};
				};

				tcpwm1_grp0_cnt: tcpwm@40580000 {
					compatible = "infineon,tcpwm";
					reg = <0x40580000 0x2A00>;
					#address-cells = <1>;
					#size-cells = <1>;
					resolution = <16>;
					status = "disabled";

					counter1_0_0: counter@40580000 {
						compatible = "infineon,tcpwm-counter";
						reg = <0x40580000 0x80>;
						system-interrupts = <435 4>;
						status = "disabled";
					};

					counter1_0_1: counter@40580080 {
						compatible = "infineon,tcpwm-counter";
						reg = <0x40580080 0x80>;
						system-interrupts = <436 4>;
						status = "disabled";
					};

					counter1_0_2: counter@40580100 {
						compatible = "infineon,tcpwm-counter";
						reg = <0x40580100 0x80>;
						system-interrupts = <437 4>;
						status = "disabled";
					};

					counter1_0_3: counter@40580180 {
						compatible = "infineon,tcpwm-counter";
						reg = <0x40580180 0x80>;
						system-interrupts = <438 4>;
						status = "disabled";
					};

					counter1_0_4: counter@40580200 {
						compatible = "infineon,tcpwm-counter";
						reg = <0x40580200 0x80>;
						system-interrupts = <439 4>;
						status = "disabled";
					};

					counter1_0_5: counter@40580280 {
						compatible = "infineon,tcpwm-counter";
						reg = <0x40580280 0x80>;
						system-interrupts = <440 4>;
						status = "disabled";
					};

					counter1_0_6: counter@40580300 {
						compatible = "infineon,tcpwm-counter";
						reg = <0x40580300 0x80>;
						system-interrupts = <441 4>;
						status = "disabled";
					};

					counter1_0_7: counter@40580380 {
						compatible = "infineon,tcpwm-counter";
						reg = <0x40580380 0x80>;
						system-interrupts = <442 4>;
						status = "disabled";
					};

					counter1_0_8: counter@40580400 {
						compatible = "infineon,tcpwm-counter";
						reg = <0x40580400 0x80>;
						system-interrupts = <443 4>;
						status = "disabled";
					};

					counter1_0_9: counter@40580480 {
						compatible = "infineon,tcpwm-counter";
						reg = <0x40580480 0x80>;
						system-interrupts = <444 4>;
						status = "disabled";
					};

					counter1_0_10: counter@40580500 {
						compatible = "infineon,tcpwm-counter";
						reg = <0x40580500 0x80>;
						system-interrupts = <445 4>;
						status = "disabled";
					};

					counter1_0_11: counter@40580580 {
						compatible = "infineon,tcpwm-counter";
						reg = <0x40580580 0x80>;
						system-interrupts = <446 4>;
						status = "disabled";
					};

					counter1_0_12: counter@40580600 {
						compatible = "infineon,tcpwm-counter";
						reg = <0x40580600 0x80>;
						system-interrupts = <447 4>;
						status = "disabled";
					};

					counter1_0_13: counter@40580680 {
						compatible = "infineon,tcpwm-counter";
						reg = <0x40580680 0x80>;
						system-interrupts = <448 4>;
						status = "disabled";
					};

					counter1_0_14: counter@40580700 {
						compatible = "infineon,tcpwm-counter";
						reg = <0x40580700 0x80>;
						system-interrupts = <449 4>;
						status = "disabled";
					};

					counter1_0_15: counter@40580780 {
						compatible = "infineon,tcpwm-counter";
						reg = <0x40580780 0x80>;
						system-interrupts = <450 4>;
						status = "disabled";
					};

					counter1_0_16: counter@40580800 {
						compatible = "infineon,tcpwm-counter";
						reg = <0x40580800 0x80>;
						system-interrupts = <451 4>;
						status = "disabled";
					};

					counter1_0_17: counter@40580880 {
						compatible = "infineon,tcpwm-counter";
						reg = <0x40580880 0x80>;
						system-interrupts = <452 4>;
						status = "disabled";
					};

					counter1_0_18: counter@40580900 {
						compatible = "infineon,tcpwm-counter";
						reg = <0x40580900 0x80>;
						system-interrupts = <453 4>;
						status = "disabled";
					};

					counter1_0_19: counter@40580980 {
						compatible = "infineon,tcpwm-counter";
						reg = <0x40580980 0x80>;
						system-interrupts = <454 4>;
						status = "disabled";
					};

					counter1_0_20: counter@40580a00 {
						compatible = "infineon,tcpwm-counter";
						reg = <0x40580a00 0x80>;
						system-interrupts = <455 4>;
						status = "disabled";
					};

					counter1_0_21: counter@40580a80 {
						compatible = "infineon,tcpwm-counter";
						reg = <0x40580a80 0x80>;
						system-interrupts = <456 4>;
						status = "disabled";
					};

					counter1_0_22: counter@40580b00 {
						compatible = "infineon,tcpwm-counter";
						reg = <0x40580b00 0x80>;
						system-interrupts = <457 4>;
						status = "disabled";
					};

					counter1_0_23: counter@40580b80 {
						compatible = "infineon,tcpwm-counter";
						reg = <0x40580b80 0x80>;
						system-interrupts = <458 4>;
						status = "disabled";
					};

					counter1_0_24: counter@40580c00 {
						compatible = "infineon,tcpwm-counter";
						reg = <0x40580c00 0x80>;
						system-interrupts = <459 4>;
						status = "disabled";
					};

					counter1_0_25: counter@40580c80 {
						compatible = "infineon,tcpwm-counter";
						reg = <0x40580c80 0x80>;
						system-interrupts = <460 4>;
						status = "disabled";
					};

					counter1_0_26: counter@40580d00 {
						compatible = "infineon,tcpwm-counter";
						reg = <0x40580d00 0x80>;
						system-interrupts = <461 4>;
						status = "disabled";
					};

					counter1_0_27: counter@40580d80 {
						compatible = "infineon,tcpwm-counter";
						reg = <0x40580d80 0x80>;
						system-interrupts = <462 4>;
						status = "disabled";
					};

					counter1_0_28: counter@40580e00 {
						compatible = "infineon,tcpwm-counter";
						reg = <0x40580e00 0x80>;
						system-interrupts = <463 4>;
						status = "disabled";
					};

					counter1_0_29: counter@40580e80 {
						compatible = "infineon,tcpwm-counter";
						reg = <0x40580e80 0x80>;
						system-interrupts = <464 4>;
						status = "disabled";
					};

					counter1_0_30: counter@40580f00 {
						compatible = "infineon,tcpwm-counter";
						reg = <0x40580f00 0x80>;
						system-interrupts = <465 4>;
						status = "disabled";
					};

					counter1_0_31: counter@40580f80 {
						compatible = "infineon,tcpwm-counter";
						reg = <0x40580f80 0x80>;
						system-interrupts = <466 4>;
						status = "disabled";
					};

					counter1_0_32: counter@40581000 {
						compatible = "infineon,tcpwm-counter";
						reg = <0x40581000 0x80>;
						system-interrupts = <467 4>;
						status = "disabled";
					};

					counter1_0_33: counter@40581080 {
						compatible = "infineon,tcpwm-counter";
						reg = <0x40581080 0x80>;
						system-interrupts = <468 4>;
						status = "disabled";
					};

					counter1_0_34: counter@40581100 {
						compatible = "infineon,tcpwm-counter";
						reg = <0x40581100 0x80>;
						system-interrupts = <469 4>;
						status = "disabled";
					};

					counter1_0_35: counter@40581180 {
						compatible = "infineon,tcpwm-counter";
						reg = <0x40581180 0x80>;
						system-interrupts = <470 4>;
						status = "disabled";
					};

					counter1_0_36: counter@40581200 {
						compatible = "infineon,tcpwm-counter";
						reg = <0x40581200 0x80>;
						system-interrupts = <471 4>;
						status = "disabled";
					};

					counter1_0_37: counter@40581280 {
						compatible = "infineon,tcpwm-counter";
						reg = <0x40581280 0x80>;
						system-interrupts = <472 4>;
						status = "disabled";
					};

					counter1_0_38: counter@40581300 {
						compatible = "infineon,tcpwm-counter";
						reg = <0x40581300 0x80>;
						system-interrupts = <473 4>;
						status = "disabled";
					};

					counter1_0_39: counter@40581380 {
						compatible = "infineon,tcpwm-counter";
						reg = <0x40581380 0x80>;
						system-interrupts = <474 4>;
						status = "disabled";
					};

					counter1_0_40: counter@40581400 {
						compatible = "infineon,tcpwm-counter";
						reg = <0x40581400 0x80>;
						system-interrupts = <475 4>;
						status = "disabled";
					};

					counter1_0_41: counter@40581480 {
						compatible = "infineon,tcpwm-counter";
						reg = <0x40581480 0x80>;
						system-interrupts = <476 4>;
						status = "disabled";
					};

					counter1_0_42: counter@40581500 {
						compatible = "infineon,tcpwm-counter";
						reg = <0x40581500 0x80>;
						system-interrupts = <477 4>;
						status = "disabled";
					};

					counter1_0_43: counter@40581580 {
						compatible = "infineon,tcpwm-counter";
						reg = <0x40581580 0x80>;
						system-interrupts = <478 4>;
						status = "disabled";
					};

					counter1_0_44: counter@40581600 {
						compatible = "infineon,tcpwm-counter";
						reg = <0x40581600 0x80>;
						system-interrupts = <479 4>;
						status = "disabled";
					};

					counter1_0_45: counter@40581680 {
						compatible = "infineon,tcpwm-counter";
						reg = <0x40581680 0x80>;
						system-interrupts = <480 4>;
						status = "disabled";
					};

					counter1_0_46: counter@40581700 {
						compatible = "infineon,tcpwm-counter";
						reg = <0x40581700 0x80>;
						system-interrupts = <481 4>;
						status = "disabled";
					};

					counter1_0_47: counter@40581780 {
						compatible = "infineon,tcpwm-counter";
						reg = <0x40581780 0x80>;
						system-interrupts = <482 4>;
						status = "disabled";
					};

					counter1_0_48: counter@40581800 {
						compatible = "infineon,tcpwm-counter";
						reg = <0x40581800 0x80>;
						system-interrupts = <483 4>;
						status = "disabled";
					};

					counter1_0_49: counter@40581880 {
						compatible = "infineon,tcpwm-counter";
						reg = <0x40581880 0x80>;
						system-interrupts = <484 4>;
						status = "disabled";
					};

					counter1_0_50: counter@40581900 {
						compatible = "infineon,tcpwm-counter";
						reg = <0x40581900 0x80>;
						system-interrupts = <485 4>;
						status = "disabled";
					};

					counter1_0_51: counter@40581980 {
						compatible = "infineon,tcpwm-counter";
						reg = <0x40581980 0x80>;
						system-interrupts = <486 4>;
						status = "disabled";
					};

					counter1_0_52: counter@40581a00 {
						compatible = "infineon,tcpwm-counter";
						reg = <0x40581a00 0x80>;
						system-interrupts = <487 4>;
						status = "disabled";
					};

					counter1_0_53: counter@40581a80 {
						compatible = "infineon,tcpwm-counter";
						reg = <0x40581a80 0x80>;
						system-interrupts = <488 4>;
						status = "disabled";
					};

					counter1_0_54: counter@40581b00 {
						compatible = "infineon,tcpwm-counter";
						reg = <0x40581b00 0x80>;
						system-interrupts = <489 4>;
						status = "disabled";
					};

					counter1_0_55: counter@40581b80 {
						compatible = "infineon,tcpwm-counter";
						reg = <0x40581b80 0x80>;
						system-interrupts = <490 4>;
						status = "disabled";
					};

					counter1_0_56: counter@40581c00 {
						compatible = "infineon,tcpwm-counter";
						reg = <0x40581c00 0x80>;
						system-interrupts = <491 4>;
						status = "disabled";
					};

					counter1_0_57: counter@40581c80 {
						compatible = "infineon,tcpwm-counter";
						reg = <0x40581c80 0x80>;
						system-interrupts = <492 4>;
						status = "disabled";
					};

					counter1_0_58: counter@40581d00 {
						compatible = "infineon,tcpwm-counter";
						reg = <0x40581d00 0x80>;
						system-interrupts = <493 4>;
						status = "disabled";
					};

					counter1_0_59: counter@40581d80 {
						compatible = "infineon,tcpwm-counter";
						reg = <0x40581d80 0x80>;
						system-interrupts = <494 4>;
						status = "disabled";
					};

					counter1_0_60: counter@40581e00 {
						compatible = "infineon,tcpwm-counter";
						reg = <0x40581e00 0x80>;
						system-interrupts = <495 4>;
						status = "disabled";
					};

					counter1_0_61: counter@40581e80 {
						compatible = "infineon,tcpwm-counter";
						reg = <0x40581e80 0x80>;
						system-interrupts = <496 4>;
						status = "disabled";
					};

					counter1_0_62: counter@40581f00 {
						compatible = "infineon,tcpwm-counter";
						reg = <0x40581f00 0x80>;
						system-interrupts = <497 4>;
						status = "disabled";
					};

					counter1_0_63: counter@40581f80 {
						compatible = "infineon,tcpwm-counter";
						reg = <0x40581f80 0x80>;
						system-interrupts = <498 4>;
						status = "disabled";
					};

					counter1_0_64: counter@40582000 {
						compatible = "infineon,tcpwm-counter";
						reg = <0x40582000 0x80>;
						system-interrupts = <499 4>;
						status = "disabled";
					};

					counter1_0_65: counter@40582080 {
						compatible = "infineon,tcpwm-counter";
						reg = <0x40582080 0x80>;
						system-interrupts = <500 4>;
						status = "disabled";
					};

					counter1_0_66: counter@40582100 {
						compatible = "infineon,tcpwm-counter";
						reg = <0x40582100 0x80>;
						system-interrupts = <501 4>;
						status = "disabled";
					};

					counter1_0_67: counter@40582180 {
						compatible = "infineon,tcpwm-counter";
						reg = <0x40582180 0x80>;
						system-interrupts = <502 4>;
						status = "disabled";
					};

					counter1_0_68: counter@40582200 {
						compatible = "infineon,tcpwm-counter";
						reg = <0x40582200 0x80>;
						system-interrupts = <503 4>;
						status = "disabled";
					};

					counter1_0_69: counter@40582280 {
						compatible = "infineon,tcpwm-counter";
						reg = <0x40582280 0x80>;
						system-interrupts = <504 4>;
						status = "disabled";
					};

					counter1_0_70: counter@40582300 {
						compatible = "infineon,tcpwm-counter";
						reg = <0x40582300 0x80>;
						system-interrupts = <505 4>;
						status = "disabled";
					};

					counter1_0_71: counter@40582380 {
						compatible = "infineon,tcpwm-counter";
						reg = <0x40582380 0x80>;
						system-interrupts = <506 4>;
						status = "disabled";
					};

					counter1_0_72: counter@40582400 {
						compatible = "infineon,tcpwm-counter";
						reg = <0x40582400 0x80>;
						system-interrupts = <507 4>;
						status = "disabled";
					};

					counter1_0_73: counter@40582480 {
						compatible = "infineon,tcpwm-counter";
						reg = <0x40582480 0x80>;
						system-interrupts = <508 4>;
						status = "disabled";
					};

					counter1_0_74: counter@40582500 {
						compatible = "infineon,tcpwm-counter";
						reg = <0x40582500 0x80>;
						system-interrupts = <509 4>;
						status = "disabled";
					};

					counter1_0_75: counter@40582580 {
						compatible = "infineon,tcpwm-counter";
						reg = <0x40582580 0x80>;
						system-interrupts = <510 4>;
						status = "disabled";
					};

					counter1_0_76: counter@40582600 {
						compatible = "infineon,tcpwm-counter";
						reg = <0x40582600 0x80>;
						system-interrupts = <511 4>;
						status = "disabled";
					};

					counter1_0_77: counter@40582680 {
						compatible = "infineon,tcpwm-counter";
						reg = <0x40582680 0x80>;
						system-interrupts = <512 4>;
						status = "disabled";
					};

					counter1_0_78: counter@40582700 {
						compatible = "infineon,tcpwm-counter";
						reg = <0x40582700 0x80>;
						system-interrupts = <513 4>;
						status = "disabled";
					};

					counter1_0_79: counter@40582780 {
						compatible = "infineon,tcpwm-counter";
						reg = <0x40582780 0x80>;
						system-interrupts = <514 4>;
						status = "disabled";
					};

					counter1_0_80: counter@40582800 {
						compatible = "infineon,tcpwm-counter";
						reg = <0x40582800 0x80>;
						system-interrupts = <515 4>;
						status = "disabled";
					};

					counter1_0_81: counter@40582880 {
						compatible = "infineon,tcpwm-counter";
						reg = <0x40582880 0x80>;
						system-interrupts = <516 4>;
						status = "disabled";
					};

					counter1_0_82: counter@40582900 {
						compatible = "infineon,tcpwm-counter";
						reg = <0x40582900 0x80>;
						system-interrupts = <517 4>;
						status = "disabled";
					};

					counter1_0_83: counter@40582980 {
						compatible = "infineon,tcpwm-counter";
						reg = <0x40582980 0x80>;
						system-interrupts = <518 4>;
						status = "disabled";
					};
				};
			};

			tcpwm1_grp1: tcpwm@40588000 {
				reg = <0x40588000 0x600>;
				#address-cells = <1>;
				#size-cells = <1>;
				tcpwm1_grp1_pwm: pwm@40588000 {
					compatible = "infineon,cat1-pwm";
					reg = <0x40588000 0x600>;
					#address-cells = <1>;
					#size-cells = <0>;
					#pwm-cells = <3>;
					resolution = <16>;
					status = "disabled";

					pwm1_ch1_0: channel@0 {
						reg = <0x0>;
						system-interrupts = <522 4>;
						status = "disabled";
					};

					pwm1_ch1_1: channel@1 {
						reg = <0x1>;
						system-interrupts = <523 4>;
						status = "disabled";
					};

					pwm1_ch1_2: channel@2 {
						reg = <0x2>;
						system-interrupts = <524 4>;
						status = "disabled";
					};

					pwm1_ch1_3: channel@3 {
						reg = <0x3>;
						system-interrupts = <525 4>;
						status = "disabled";
					};

					pwm1_ch1_4: channel@4 {
						reg = <0x4>;
						system-interrupts = <526 4>;
						status = "disabled";
					};

					pwm1_ch1_5: channel@5 {
						reg = <0x5>;
						system-interrupts = <527 4>;
						status = "disabled";
					};

					pwm1_ch1_6: channel@6 {
						reg = <0x6>;
						system-interrupts = <527 4>;
						status = "disabled";
					};

					pwm1_ch1_7: channel@7 {
						reg = <0x7>;
						system-interrupts = <529 4>;
						status = "disabled";
					};

					pwm1_ch1_8: channel@8 {
						reg = <0x8>;
						system-interrupts = <530 4>;
						status = "disabled";
					};

					pwm1_ch1_9: channel@9 {
						reg = <0x9>;
						system-interrupts = <531 4>;
						status = "disabled";
					};

					pwm1_ch1_10: channel@10 {
						reg = <0xA>;
						system-interrupts = <532 4>;
						status = "disabled";
					};

					pwm1_ch1_11: channel@11 {
						reg = <0xB>;
						system-interrupts = <533 4>;
						status = "disabled";
					};
				};

				tcpwm1_grp1_cnt: tcpwm@40588000 {
					compatible = "infineon,tcpwm";
					reg = <0x40588000 0x600>;
					#address-cells = <1>;
					#size-cells = <1>;
					resolution = <16>;
					status = "disabled";

					counter1_1_0: counter@40588000 {
						compatible = "infineon,tcpwm-counter";
						reg = <0x40588000 0x80>;
						system-interrupts = <522 4>;
						status = "disabled";
					};

					counter1_1_1: counter@40588080 {
						compatible = "infineon,tcpwm-counter";
						reg = <0x40588080 0x80>;
						system-interrupts = <523 4>;
						status = "disabled";
					};

					counter1_1_2: counter@40588100 {
						compatible = "infineon,tcpwm-counter";
						reg = <0x40588100 0x80>;
						system-interrupts = <524 4>;
						status = "disabled";
					};

					counter1_1_3: counter@40588180 {
						compatible = "infineon,tcpwm-counter";
						reg = <0x40588180 0x80>;
						system-interrupts = <525 4>;
						status = "disabled";
					};

					counter1_1_4: counter@40588200 {
						compatible = "infineon,tcpwm-counter";
						reg = <0x40588200 0x80>;
						system-interrupts = <526 4>;
						status = "disabled";
					};

					counter1_1_5: counter@40588280 {
						compatible = "infineon,tcpwm-counter";
						reg = <0x40588280 0x80>;
						system-interrupts = <527 4>;
						status = "disabled";
					};

					counter1_1_6: counter@40588300 {
						compatible = "infineon,tcpwm-counter";
						reg = <0x40588300 0x80>;
						system-interrupts = <528 4>;
						status = "disabled";
					};

					counter1_1_7: counter@40588380 {
						compatible = "infineon,tcpwm-counter";
						reg = <0x40588380 0x80>;
						system-interrupts = <529 4>;
						status = "disabled";
					};

					counter1_1_8: counter@40588400 {
						compatible = "infineon,tcpwm-counter";
						reg = <0x40588400 0x80>;
						system-interrupts = <530 4>;
						status = "disabled";
					};

					counter1_1_9: counter@40588480 {
						compatible = "infineon,tcpwm-counter";
						reg = <0x40588480 0x80>;
						system-interrupts = <531 4>;
						status = "disabled";
					};

					counter1_1_10: counter@40588500 {
						compatible = "infineon,tcpwm-counter";
						reg = <0x40588500 0x80>;
						system-interrupts = <532 4>;
						status = "disabled";
					};

					counter1_1_11: counter@40588580 {
						compatible = "infineon,tcpwm-counter";
						reg = <0x40588580 0x80>;
						system-interrupts = <533 4>;
						status = "disabled";
					};
				};
			};

			tcpwm1_grp2: tcpwm@40590000 {
				reg = <0x40590000 0x680>;
				#address-cells = <1>;
				#size-cells = <1>;
				tcpwm1_grp2_pwm: pwm@40590000 {
					compatible = "infineon,cat1-pwm";
					reg = <0x40590000 0x680>;
					#address-cells = <1>;
					#size-cells = <0>;
					#pwm-cells = <3>;
					resolution = <32>;
					status = "disabled";

					pwm1_ch2_0: channel@0 {
						reg = <0x0>;
						system-interrupts = <537 4>;
						status = "disabled";
					};

					pwm1_ch2_1: channel@1 {
						reg = <0x1>;
						system-interrupts = <538 4>;
						status = "disabled";
					};

					pwm1_ch2_2: channel@2 {
						reg = <0x2>;
						system-interrupts = <539 4>;
						status = "disabled";
					};

					pwm1_ch2_3: channel@3 {
						reg = <0x3>;
						system-interrupts = <540 4>;
						status = "disabled";
					};

					pwm1_ch2_4: channel@4 {
						reg = <0x4>;
						system-interrupts = <541 4>;
						status = "disabled";
					};

					pwm1_ch2_5: channel@5 {
						reg = <0x5>;
						system-interrupts = <542 4>;
						status = "disabled";
					};

					pwm1_ch2_6: channel@6 {
						reg = <0x6>;
						system-interrupts = <543 4>;
						status = "disabled";
					};

					pwm1_ch2_7: channel@7 {
						reg = <0x7>;
						system-interrupts = <544 4>;
						status = "disabled";
					};

					pwm1_ch2_8: channel@8 {
						reg = <0x8>;
						system-interrupts = <545 4>;
						status = "disabled";
					};

					pwm1_ch2_9: channel@9 {
						reg = <0x9>;
						system-interrupts = <546 4>;
						status = "disabled";
					};

					pwm1_ch2_10: channel@10 {
						reg = <0xA>;
						system-interrupts = <547 4>;
						status = "disabled";
					};

					pwm1_ch2_11: channel@11 {
						reg = <0xB>;
						system-interrupts = <548 4>;
						status = "disabled";
					};

					pwm1_ch2_12: channel@12 {
						reg = <0xC>;
						system-interrupts = <549 4>;
						status = "disabled";
					};
				};

				tcpwm1_grp2_tgpio: tgpio@40590000 {
					compatible = "infineon,tcpwm-tgpio";
					reg = <0x40590000 0x680>;
					#address-cells = <1>;
					#size-cells = <0>;
					status = "disabled";

					tgpio1_ch2_0: channel@0 {
						reg = <0x0>;
						system-interrupts = <537 4>;
						status = "disabled";
					};

					tgpio1_ch2_1: channel@1 {
						reg = <0x1>;
						system-interrupts = <538 4>;
						status = "disabled";
					};

					tgpio1_ch2_2: channel@2 {
						reg = <0x2>;
						system-interrupts = <539 4>;
						status = "disabled";
					};

					tgpio1_ch2_3: channel@3 {
						reg = <0x3>;
						system-interrupts = <540 4>;
						status = "disabled";
					};

					tgpio1_ch2_4: channel@4 {
						reg = <0x4>;
						system-interrupts = <541 4>;
						status = "disabled";
					};

					tgpio1_ch2_5: channel@5 {
						reg = <0x5>;
						system-interrupts = <542 4>;
						status = "disabled";
					};

					tgpio1_ch2_6: channel@6 {
						reg = <0x6>;
						system-interrupts = <543 4>;
						status = "disabled";
					};

					tgpio1_ch2_7: channel@7 {
						reg = <0x7>;
						system-interrupts = <544 4>;
						status = "disabled";
					};

					tgpio1_ch2_8: channel@8 {
						reg = <0x8>;
						system-interrupts = <545 4>;
						status = "disabled";
					};

					tgpio1_ch2_9: channel@9 {
						reg = <0x9>;
						system-interrupts = <546 4>;
						status = "disabled";
					};

					tgpio1_ch2_10: channel@10 {
						reg = <0xA>;
						system-interrupts = <547 4>;
						status = "disabled";
					};

					tgpio1_ch2_11: channel@11 {
						reg = <0xB>;
						system-interrupts = <548 4>;
						status = "disabled";
					};

					tgpio1_ch2_12: channel@12 {
						reg = <0xC>;
						system-interrupts = <549 4>;
						status = "disabled";
					};
				};

				tcpwm1_grp2_cnt: tcpwm@40590000 {
					compatible = "infineon,tcpwm";
					reg = <0x40590000 0x680>;
					#address-cells = <1>;
					#size-cells = <1>;
					resolution = <32>;
					status = "disabled";

					counter1_2_0: counter@40590000 {
						compatible = "infineon,tcpwm-counter";
						reg = <0x40590000 0x80>;
						system-interrupts = <537 4>;
						status = "disabled";
					};

					counter1_2_1: counter@40590080 {
						compatible = "infineon,tcpwm-counter";
						reg = <0x40590080 0x80>;
						system-interrupts = <538 4>;
						status = "disabled";
					};

					counter1_2_2: counter@40590100 {
						compatible = "infineon,tcpwm-counter";
						reg = <0x40590100 0x80>;
						system-interrupts = <539 4>;
						status = "disabled";
					};

					counter1_2_3: counter@40590180 {
						compatible = "infineon,tcpwm-counter";
						reg = <0x40590180 0x80>;
						system-interrupts = <540 4>;
						status = "disabled";
					};

					counter1_2_4: counter@40590200 {
						compatible = "infineon,tcpwm-counter";
						reg = <0x40590200 0x80>;
						system-interrupts = <541 4>;
						status = "disabled";
					};

					counter1_2_5: counter@40590280 {
						compatible = "infineon,tcpwm-counter";
						reg = <0x40590280 0x80>;
						system-interrupts = <542 4>;
						status = "disabled";
					};

					counter1_2_6: counter@40590300 {
						compatible = "infineon,tcpwm-counter";
						reg = <0x40590300 0x80>;
						system-interrupts = <543 4>;
						status = "disabled";
					};

					counter1_2_7: counter@40590380 {
						compatible = "infineon,tcpwm-counter";
						reg = <0x40590380 0x80>;
						system-interrupts = <544 4>;
						status = "disabled";
					};

					counter1_2_8: counter@40590400 {
						compatible = "infineon,tcpwm-counter";
						reg = <0x40590400 0x80>;
						system-interrupts = <545 4>;
						status = "disabled";
					};

					counter1_2_9: counter@40590480 {
						compatible = "infineon,tcpwm-counter";
						reg = <0x40590480 0x80>;
						system-interrupts = <546 4>;
						status = "disabled";
					};

					counter1_2_10: counter@40590500 {
						compatible = "infineon,tcpwm-counter";
						reg = <0x40590500 0x80>;
						system-interrupts = <547 4>;
						status = "disabled";
					};

					counter1_2_11: counter@40590580 {
						compatible = "infineon,tcpwm-counter";
						reg = <0x40590580 0x80>;
						system-interrupts = <548 4>;
						status = "disabled";
					};

					counter1_2_12: counter@40590600 {
						compatible = "infineon,tcpwm-counter";
						reg = <0x40590600 0x80>;
						system-interrupts = <549 4>;
						status = "disabled";
					};
				};
			};
		};

		dma0: dw@40280000 {
			#dma-cells = <1>;
			compatible = "infineon,cat1-dma-pdl";
			reg = <0x40280000 0x10000>;
			dma-channels = <143>;
			interrupts = <227 6>, /* CH0 */
								<228 6>, /* CH1 */
								<229 6>, /* CH2 */
								<230 6>, /* CH3 */
								<231 6>, /* CH4 */
								<232 6>, /* CH5 */
								<233 6>, /* CH6 */
								<234 6>, /* CH7 */
								<235 6>, /* CH8 */
								<236 6>, /* CH9 */
								<237 6>, /* CH10 */
								<238 6>, /* CH11 */
								<239 6>, /* CH12 */
								<240 6>, /* CH13 */
								<241 6>, /* CH14 */
								<242 6>, /* CH15 */
								<243 6>, /* CH16 */
								<244 6>, /* CH17 */
								<245 6>, /* CH18 */
								<246 6>, /* CH19 */
								<247 6>, /* CH20 */
								<248 6>, /* CH21 */
								<249 6>, /* CH22 */
								<250 6>, /* CH23 */
								<251 6>, /* CH24 */
								<252 6>, /* CH25 */
								<253 6>, /* CH26 */
								<254 6>, /* CH27 */
								<255 6>, /* CH28 */
								<256 6>, /* CH29 */
								<257 6>, /* CH30 */
								<258 6>, /* CH31 */
								<259 6>, /* CH32 */
								<260 6>, /* CH33 */
								<261 6>, /* CH34 */
								<262 6>, /* CH35 */
								<263 6>, /* CH36 */
								<264 6>, /* CH37 */
								<265 6>, /* CH38 */
								<266 6>, /* CH39 */
								<267 6>, /* CH40 */
								<268 6>, /* CH41 */
								<269 6>, /* CH42 */
								<270 6>, /* CH43 */
								<271 6>, /* CH44 */
								<272 6>, /* CH45 */
								<273 6>, /* CH46 */
								<274 6>, /* CH47 */
								<275 6>, /* CH48 */
								<276 6>, /* CH49 */
								<277 6>, /* CH50 */
								<278 6>, /* CH51 */
								<279 6>, /* CH52 */
								<280 6>, /* CH53 */
								<281 6>, /* CH54 */
								<282 6>, /* CH55 */
								<283 6>, /* CH56 */
								<284 6>, /* CH57 */
								<285 6>, /* CH58 */
								<286 6>, /* CH59 */
								<287 6>, /* CH60 */
								<288 6>, /* CH61 */
								<289 6>, /* CH62 */
								<290 6>, /* CH63 */
								<291 6>, /* CH64 */
								<292 6>, /* CH65 */
								<293 6>, /* CH66 */
								<294 6>, /* CH67 */
								<295 6>, /* CH68 */
								<296 6>, /* CH69 */
								<297 6>, /* CH70 */
								<298 6>, /* CH71 */
								<299 6>, /* CH72 */
								<300 6>, /* CH73 */
								<301 6>, /* CH74 */
								<302 6>, /* CH75 */
								<303 6>, /* CH76 */
								<304 6>, /* CH77 */
								<305 6>, /* CH78 */
								<306 6>, /* CH79 */
								<307 6>, /* CH80 */
								<308 6>, /* CH81 */
								<309 6>, /* CH82 */
								<310 6>, /* CH83 */
								<311 6>, /* CH84 */
								<312 6>, /* CH85 */
								<313 6>, /* CH86 */
								<314 6>, /* CH87 */
								<315 6>, /* CH88 */
								<316 6>, /* CH89 */
								<317 6>, /* CH90 */
								<318 6>, /* CH91 */
								<319 6>, /* CH92 */
								<320 6>, /* CH93 */
								<321 6>, /* CH94 */
								<322 6>, /* CH95 */
								<323 6>, /* CH96 */
								<324 6>, /* CH97 */
								<325 6>, /* CH98 */
								<326 6>, /* CH99 */
								<327 6>, /* CH100 */
								<328 6>, /* CH101 */
								<329 6>, /* CH102 */
								<330 6>, /* CH103 */
								<331 6>, /* CH104 */
								<332 6>, /* CH105 */
								<333 6>, /* CH106 */
								<334 6>, /* CH107 */
								<335 6>, /* CH108 */
								<336 6>, /* CH109 */
								<337 6>, /* CH110 */
								<338 6>, /* CH111 */
								<339 6>, /* CH112 */
								<340 6>, /* CH113 */
								<341 6>, /* CH114 */
								<342 6>, /* CH115 */
								<343 6>, /* CH116 */
								<344 6>, /* CH117 */
								<345 6>, /* CH118 */
								<346 6>, /* CH119 */
								<347 6>, /* CH120 */
								<348 6>, /* CH121 */
								<349 6>, /* CH122 */
								<350 6>, /* CH123 */
								<351 6>, /* CH124 */
								<352 6>, /* CH125 */
								<353 6>, /* CH126 */
								<354 6>, /* CH127 */
								<355 6>, /* CH128 */
								<356 6>, /* CH129 */
								<357 6>, /* CH130 */
								<358 6>, /* CH131 */
								<359 6>, /* CH132 */
								<360 6>, /* CH133 */
								<361 6>, /* CH134 */
								<362 6>, /* CH135 */
								<363 6>, /* CH136 */
								<364 6>, /* CH137 */
								<365 6>, /* CH138 */
								<366 6>, /* CH139 */
								<367 6>, /* CH140 */
								<368 6>, /* CH141 */
								<369 6>; /* CH142 */
			status = "disabled";
		};
		dma1: dw@40290000 {
			#dma-cells = <1>;
			compatible = "infineon,cat1-dma-pdl";
			reg = <0x40290000 0x10000>;
			dma-channels = <65>;
			interrupts = <370 6>, /* CH0 */
								<371 6>, /* CH1 */
								<372 6>, /* CH2 */
								<373 6>, /* CH3 */
								<374 6>, /* CH4 */
								<375 6>, /* CH5 */
								<376 6>, /* CH6 */
								<377 6>, /* CH7 */
								<378 6>, /* CH8 */
								<379 6>, /* CH9 */
								<380 6>, /* CH10 */
								<381 6>, /* CH11 */
								<382 6>, /* CH12 */
								<383 6>, /* CH13 */
								<384 6>, /* CH14 */
								<385 6>, /* CH15 */
								<386 6>, /* CH16 */
								<387 6>, /* CH17 */
								<388 6>, /* CH18 */
								<389 6>, /* CH19 */
								<390 6>, /* CH20 */
								<391 6>, /* CH21 */
								<392 6>, /* CH22 */
								<393 6>, /* CH23 */
								<394 6>, /* CH24 */
								<395 6>, /* CH25 */
								<396 6>, /* CH26 */
								<397 6>, /* CH27 */
								<398 6>, /* CH28 */
								<399 6>, /* CH29 */
								<400 6>, /* CH30 */
								<401 6>, /* CH31 */
								<402 6>, /* CH32 */
								<403 6>, /* CH33 */
								<404 6>, /* CH34 */
								<405 6>, /* CH35 */
								<406 6>, /* CH36 */
								<407 6>, /* CH37 */
								<408 6>, /* CH38 */
								<409 6>, /* CH39 */
								<410 6>, /* CH40 */
								<411 6>, /* CH41 */
								<412 6>, /* CH42 */
								<413 6>, /* CH43 */
								<414 6>, /* CH44 */
								<415 6>, /* CH45 */
								<416 6>, /* CH46 */
								<417 6>, /* CH47 */
								<418 6>, /* CH48 */
								<419 6>, /* CH49 */
								<420 6>, /* CH50 */
								<421 6>, /* CH51 */
								<422 6>, /* CH52 */
								<423 6>, /* CH53 */
								<424 6>, /* CH54 */
								<425 6>, /* CH55 */
								<426 6>, /* CH56 */
								<427 6>, /* CH57 */
								<428 6>, /* CH58 */
								<429 6>, /* CH59 */
								<430 6>, /* CH60 */
								<431 6>, /* CH61 */
								<432 6>, /* CH62 */
								<433 6>, /* CH63 */
								<434 6>; /* CH64 */
			status = "disabled";
		};

		sdhc0: sdhc@40460000 {
			compatible = "infineon,cat1-sdhc-sdio";
			reg = <0x40460000 0x2000>;
			system-interrupts = <563 6>, /* SDIO wakeup interrupt for mxsdhc */
								<562 6>; /* Consolidated interrupt for mxsdhc */
			status = "disabled";
		};

		adc0: adc@40900000 {
			compatible = "infineon,ifx-sar";
			reg = <0x40900000 0x1000>;
			#io-channel-cells = <1>;
			system-interrupts = <123 3>;
			clock-frequency = <26670000>;
			ifx,peri-group = <IFX_PERI_GRP_INST_SEL(1, 0)>;
			ifx,peri-clk = <0x012A>;
			ifx,peri-div = <0>; /* 8-bit divider */
			ifx,peri-div-inst = <2>;
		};

		adc1: adc@40901000 {
			compatible = "infineon,ifx-sar";
			reg = <0x40901000 0x1000>;
			#io-channel-cells = <1>;
			system-interrupts = <155 3>;
			clock-frequency = <26670000>;
			ifx,peri-group = <IFX_PERI_GRP_INST_SEL(1, 0)>;
			ifx,peri-clk = <0x012B>;
			ifx,peri-div = <0>; /* 8-bit divider */
			ifx,peri-div-inst = <2>;
		};

		can0_0: can@40520000 {
			compatible = "infineon,cat1-can";
			reg = <0x40520000 0x200>, <0x40530000 0xA000>;
			reg-names = "m_can", "message_ram";
			system-interrupts = <73 2>, <78 2>;
			clocks = <&clk_hf2>;
			bosch,mram-cfg = <0x0 28 8 3 3 1 3 3>;
			status = "disabled";
		};
		can0_1: can@40520200 {
			compatible = "infineon,cat1-can";
			reg = <0x40520200 0x200>, <0x40530000 0xA000>;
			reg-names = "m_can", "message_ram";
			system-interrupts = <74 2>, <79 2>;
			clocks = <&clk_hf2>;
			bosch,mram-cfg = <0x2000 28 8 3 3 1 3 3>;
			status = "disabled";
		};
		can0_2: can@40520400 {
			compatible = "infineon,cat1-can";
			reg = <0x40520400 0x200>, <0x40530000 0xA000>;
			reg-names = "m_can", "message_ram";
			system-interrupts = <75 2>, <80 2>;
			clocks = <&clk_hf2>;
			bosch,mram-cfg = <0x4000 28 8 3 3 1 3 3>;
			status = "disabled";
		};
		can0_3: can@40520600 {
			compatible = "infineon,cat1-can";
			reg = <0x40520600 0x200>, <0x40530000 0xA000>;
			reg-names = "m_can", "message_ram";
			system-interrupts = <76 2>, <81 2>;
			clocks = <&clk_hf2>;
			bosch,mram-cfg = <0x6000 28 8 3 3 1 3 3>;
			status = "disabled";
		};
		can0_4: can@40520800 {
			compatible = "infineon,cat1-can";
			reg = <0x40520800 0x200>, <0x40530000 0xA000>;
			reg-names = "m_can", "message_ram";
			system-interrupts = <77 2>, <82 2>;
			clocks = <&clk_hf2>;
			bosch,mram-cfg = <0x8000 28 8 3 3 1 3 3>;
			status = "disabled";
		};

		can1_0: can@40540000 {
			compatible = "infineon,cat1-can";
			reg = <0x40540000 0x200>, <0x40550000 0xA000>;
			reg-names = "m_can", "message_ram";
			system-interrupts = <83 3>, <88 3>;
			clocks = <&clk_hf2>;
			bosch,mram-cfg = <0x0 28 8 3 3 1 3 3>;
			status = "disabled";
		};
		can1_1: can@40540200 {
			compatible = "infineon,cat1-can";
			reg = <0x40540200 0x200>, <0x40550000 0xA000>;
			reg-names = "m_can", "message_ram";
			system-interrupts = <84 3>, <89 3>;
			clocks = <&clk_hf2>;
			bosch,mram-cfg = <0x2000 28 8 3 3 1 3 3>;
			status = "disabled";
		};
		can1_2: can@40540400 {
			compatible = "infineon,cat1-can";
			reg = <0x40540400 0x200>, <0x40550000 0xA000>;
			reg-names = "m_can", "message_ram";
			system-interrupts = <85 3>, <90 3>;
			clocks = <&clk_hf2>;
			bosch,mram-cfg = <0x4000 28 8 3 3 1 3 3>;
			status = "disabled";
		};
		can1_3: can@40540600 {
			compatible = "infineon,cat1-can";
			reg = <0x40540600 0x200>, <0x40550000 0xA000>;
			reg-names = "m_can", "message_ram";
			system-interrupts = <86 3>, <91 3>;
			clocks = <&clk_hf2>;
			bosch,mram-cfg = <0x6000 28 8 3 3 1 3 3>;
			status = "disabled";
		};
		can1_4: can@40540800 {
			compatible = "infineon,cat1-can";
			reg = <0x40540800 0x200>, <0x40550000 0xA000>;
			reg-names = "m_can", "message_ram";
			system-interrupts = <87 3>, <92 3>;
			clocks = <&clk_hf2>;
			bosch,mram-cfg = <0x8000 28 8 3 3 1 3 3>;
			status = "disabled";
		};

		eth0: ethernet@40480000 {
			compatible = "xlnx,gem-controller";
			reg = <0x40481000 0x1000>, <0x40480000 0x1000>;

			eth0_mac: ethernet {
				compatible = "xlnx,gem";
				status = "disabled";
				system-interrupts = <556 4>, <557 4>;
				amba-ahb-burst-length = <XLNX_GEM_AMBA_AHB_BURST_INCR4>;
				hw-rx-buffer-size = <XLNX_GEM_HW_RX_BUFFER_SIZE_8KB>;
				hw-rx-buffer-offset = <0>;
				hw-tx-buffer-size-full;
				rx-buffer-descriptors = <16>;
				tx-buffer-descriptors = <16>;
				rx-buffer-size = <1536>;
				tx-buffer-size = <1536>;
				discard-rx-fcs;
				unicast-hash;
			};

			eth0_mdio: mdio {
				compatible = "xlnx,gem-mdio";
				status = "disabled";
				#address-cells = <1>;
				#size-cells = <0>;
			};
		};
	};
};
